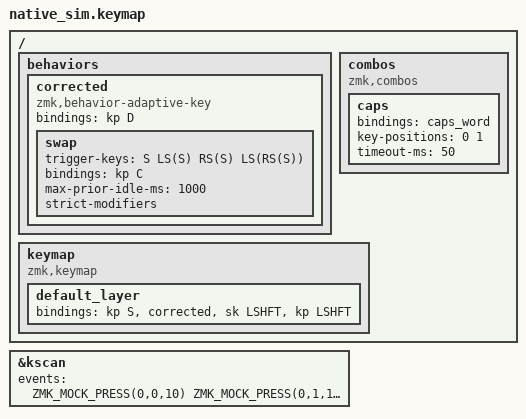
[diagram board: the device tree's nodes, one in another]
#include <behaviors.dtsi>
#include <dt-bindings/zmk/keys.h>
#include <dt-bindings/zmk/kscan_mock.h>

/ {
    behaviors {
        corrected: corrected {
            compatible = "zmk,behavior-adaptive-key";
            #binding-cells = <0>;
            bindings = <&kp D>;

            swap {
                trigger-keys = <S LS(S) RS(S) LS(RS(S))>;
                bindings = <&kp C>;
                max-prior-idle-ms = <1000>;
                strict-modifiers;
            };
        };
    };

    combos {
        compatible = "zmk,combos";

        caps {
            bindings = <&caps_word>;
            key-positions = <0 1>;
            timeout-ms = <50>;
        };
    };

    keymap {
        compatible = "zmk,keymap";

        default_layer {
            bindings = <&kp S &corrected &sk LSHFT &kp LSHFT>;
        };
    };
};

&kscan {
    events = <
        ZMK_MOCK_PRESS(0,0,10)
        ZMK_MOCK_PRESS(0,1,10)
        ZMK_MOCK_RELEASE(0,0,10)
        ZMK_MOCK_RELEASE(0,1,100)
        ZMK_MOCK_PRESS(0,0,10)
        ZMK_MOCK_RELEASE(0,0,100)
        ZMK_MOCK_PRESS(0,1,10)
        ZMK_MOCK_RELEASE(0,1,100)

        ZMK_MOCK_PRESS(0,0,10)
        ZMK_MOCK_PRESS(0,1,10)
        ZMK_MOCK_RELEASE(0,0,10)
        ZMK_MOCK_RELEASE(0,1,100)
        ZMK_MOCK_PRESS(0,0,10)
        ZMK_MOCK_RELEASE(0,0,100)
        ZMK_MOCK_PRESS(1,0,10)
        ZMK_MOCK_RELEASE(1,0,10)
        ZMK_MOCK_PRESS(0,1,10)
        ZMK_MOCK_RELEASE(0,1,100)

        ZMK_MOCK_PRESS(1,1,10)
        ZMK_MOCK_PRESS(0,0,10)
        ZMK_MOCK_RELEASE(0,0,100)
        ZMK_MOCK_PRESS(0,1,10)
        ZMK_MOCK_RELEASE(0,1,10)
        ZMK_MOCK_RELEASE(1,1,10)

        ZMK_MOCK_PRESS(0,0,10)
        ZMK_MOCK_RELEASE(0,0,100)
        ZMK_MOCK_PRESS(1,1,10)
        ZMK_MOCK_PRESS(0,1,10)
        ZMK_MOCK_RELEASE(0,1,10)
        ZMK_MOCK_RELEASE(1,1,10)
    >;
};
